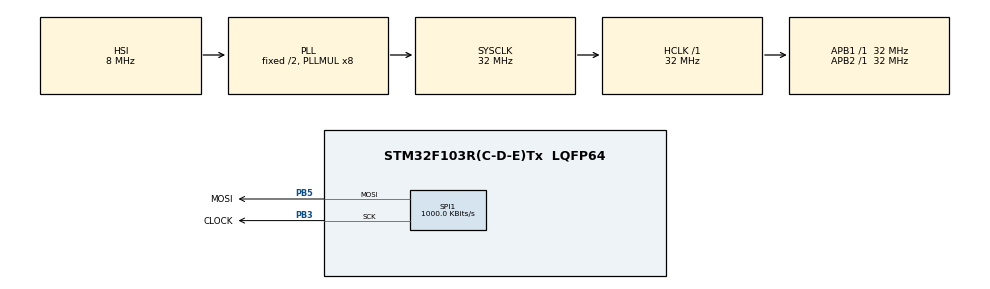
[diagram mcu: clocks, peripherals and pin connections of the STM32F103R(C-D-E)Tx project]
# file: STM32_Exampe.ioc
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Mcu.Family=STM32F1
Mcu.Name=STM32F103R(C-D-E)Tx
Mcu.Package=LQFP64
NVIC.PriorityGroup=NVIC_PRIORITYGROUP_4
PA13.Mode=Serial_Wire
PA13.Signal=SYS_JTMS-SWDIO
PA14.Mode=Serial_Wire
PA14.Signal=SYS_JTCK-SWCLK
PB3.GPIO_Label=CLOCK
PB3.GPIO_Mode=GPIO_MODE_AF_PP
PB3.GPIO_Speed=GPIO_SPEED_FREQ_MEDIUM
PB3.Mode=TX_Only_Simplex_Unidirect_Master
PB3.Signal=SPI1_SCK
PB5.GPIO_Label=MOSI
PB5.GPIO_Mode=GPIO_MODE_AF_PP
PB5.GPIO_Speed=GPIO_SPEED_FREQ_MEDIUM
PB5.Mode=TX_Only_Simplex_Unidirect_Master
PB5.Signal=SPI1_MOSI
ProjectManager.HeapSize=0x200
ProjectManager.StackSize=0x400
ProjectManager.TargetToolchain=EWARM V8.32
RCC.AHBFreq_Value=32000000
RCC.APB1Freq_Value=32000000
RCC.APB1TimFreq_Value=32000000
RCC.APB2Freq_Value=32000000
RCC.APB2TimFreq_Value=32000000
RCC.HCLKFreq_Value=32000000
RCC.PLLMUL=RCC_PLL_MUL8
RCC.SYSCLKFreq_VALUE=32000000
RCC.SYSCLKSource=RCC_SYSCLKSOURCE_PLLCLK
RCC.USBFreq_Value=32000000
SPI1.BaudRatePrescaler=SPI_BAUDRATEPRESCALER_32
SPI1.CLKPhase=SPI_PHASE_2EDGE
SPI1.CLKPolarity=SPI_POLARITY_HIGH
SPI1.CalculateBaudRate=1000.0 KBits/s
SPI1.Direction=SPI_DIRECTION_2LINES
SPI1.Mode=SPI_MODE_MASTER
SPI1.VirtualType=VM_MASTER
board=custom

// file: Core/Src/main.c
/* USER CODE BEGIN Header */
/**
  ******************************************************************************
  * @file           : main.c
  * @brief          : Main program body
  ******************************************************************************
  * @attention
  *
  * Copyright (c) 2025 STMicroelectronics.
  * All rights reserved.
  *
  * This software is licensed under terms that can be found in the LICENSE file
  * in the root directory of this software component.
  * If no LICENSE file comes with this software, it is provided AS-IS.
  *
  ******************************************************************************
  */
/* USER CODE END Header */
#include "main.h"

/* USER CODE BEGIN Includes */
#include "APA102_hw_stm32_hal.h"
#include "APA102.h"
/* USER CODE END Includes */

SPI_HandleTypeDef hspi1;

void SystemClock_Config(void);
static void MX_GPIO_Init(void);
static void MX_SPI1_Init(void);

int main(void)
{

  /* USER CODE BEGIN 1 */

    uint16_t i  = 0;
    uint8_t j   = 1;
    uint8_t q   = 9;
  /* USER CODE END 1 */

  /* MCU Configuration--------------------------------------------------------*/

  /* Reset of all peripherals, Initializes the Flash interface and the Systick. */
  HAL_Init();

  /* Configure the system clock */
  SystemClock_Config();

  /* USER CODE BEGIN SysInit */
  SystemCoreClockUpdate();
  SysTick_Config( SystemCoreClock/1000);
  /* USER CODE END SysInit */

  /* Initialize all configured peripherals */
  MX_GPIO_Init();
  MX_SPI1_Init();
  /* USER CODE BEGIN 2 */
  APA_Init();

  /* USER CODE END 2 */

  /* Infinite loop */
  /* USER CODE BEGIN WHILE */
  while (1)
  {

    /* Update the LED colors */
   for (i = 0; i < LED_BUFF_SZ; i++) {
            uint8_t hue = (uint8_t)( ( i * 5 ) + j );
            APA_SetPixelHSV( (uint16_t)i, 20, hue, 255, 120 );
        }
        /* Send the updated LED colors to the APA102 LEDs and wait a while */
        APA_sendBuffer();
        HAL_Delay( 5 );

        /* Update the hue for the next loop */
        q++;
        if ( q >= 2 ) {
            q = 0;
            j = ( j + 1 ) & 0xFF;
        }
    /* USER CODE END WHILE */

  }
}

void SystemClock_Config(void)
{
  RCC_OscInitTypeDef RCC_OscInitStruct = {0};
  RCC_ClkInitTypeDef RCC_ClkInitStruct = {0};

  /** Initializes the RCC Oscillators according to the specified parameters
  * in the RCC_OscInitTypeDef structure.
  */
  RCC_OscInitStruct.OscillatorType = RCC_OSCILLATORTYPE_HSI;
  RCC_OscInitStruct.HSIState = RCC_HSI_ON;
  RCC_OscInitStruct.HSICalibrationValue = RCC_HSICALIBRATION_DEFAULT;
  RCC_OscInitStruct.PLL.PLLState = RCC_PLL_ON;
  RCC_OscInitStruct.PLL.PLLSource = RCC_PLLSOURCE_HSI_DIV2;
  RCC_OscInitStruct.PLL.PLLMUL = RCC_PLL_MUL8;
  if (HAL_RCC_OscConfig(&RCC_OscInitStruct) != HAL_OK)
  {
    Error_Handler();
  }

  /** Initializes the CPU, AHB and APB buses clocks
  */
  RCC_ClkInitStruct.ClockType = RCC_CLOCKTYPE_HCLK|RCC_CLOCKTYPE_SYSCLK
                              |RCC_CLOCKTYPE_PCLK1|RCC_CLOCKTYPE_PCLK2;
  RCC_ClkInitStruct.SYSCLKSource = RCC_SYSCLKSOURCE_PLLCLK;
  RCC_ClkInitStruct.AHBCLKDivider = RCC_SYSCLK_DIV1;
  RCC_ClkInitStruct.APB1CLKDivider = RCC_HCLK_DIV1;
  RCC_ClkInitStruct.APB2CLKDivider = RCC_HCLK_DIV1;

  if (HAL_RCC_ClockConfig(&RCC_ClkInitStruct, FLASH_LATENCY_1) != HAL_OK)
  {
    Error_Handler();
  }
}

static void MX_SPI1_Init(void)
{

  /* SPI1 parameter configuration*/
  hspi1.Instance = SPI1;
  hspi1.Init.Mode = SPI_MODE_MASTER;
  hspi1.Init.Direction = SPI_DIRECTION_1LINE;
  hspi1.Init.DataSize = SPI_DATASIZE_8BIT;
  hspi1.Init.CLKPolarity = SPI_POLARITY_HIGH;
  hspi1.Init.CLKPhase = SPI_PHASE_2EDGE;
  hspi1.Init.NSS = SPI_NSS_SOFT;
  hspi1.Init.BaudRatePrescaler = SPI_BAUDRATEPRESCALER_128;
  hspi1.Init.FirstBit = SPI_FIRSTBIT_MSB;
  hspi1.Init.TIMode = SPI_TIMODE_DISABLE;
  hspi1.Init.CRCCalculation = SPI_CRCCALCULATION_DISABLE;
  hspi1.Init.CRCPolynomial = 10;
  if (HAL_SPI_Init(&hspi1) != HAL_OK)
  {
    Error_Handler();
  }

}

static void MX_GPIO_Init(void)
{

  /* GPIO Ports Clock Enable */
  __HAL_RCC_GPIOA_CLK_ENABLE();
  __HAL_RCC_GPIOB_CLK_ENABLE();

}

void Error_Handler(void)
{
  __disable_irq();
  while (1)
  {
  }
}
